VERSION ""

NS_ :

BS_:

BU_: XXX

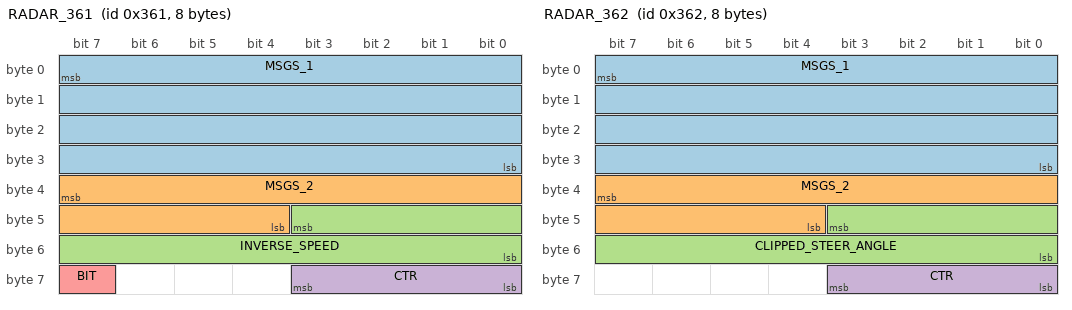
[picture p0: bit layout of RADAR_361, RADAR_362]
BO_ 865 RADAR_361: 8 XXX
 SG_ MSGS_1 : 7|32@0+ (1,0) [0|4294967295] "" XXX
 SG_ MSGS_2 : 39|12@0+ (1,0) [0|4095] "" XXX
 SG_ INVERSE_SPEED : 43|12@0- (1,0) [-2048|2047] "" XXX
 SG_ CTR : 59|4@0+ (1,0) [0|15] "" XXX
 SG_ BIT : 63|1@0+ (1,0) [0|1] "" XXX

BO_ 866 RADAR_362: 8 XXX
 SG_ MSGS_1 : 7|32@0+ (1,0) [0|4294967295] "" XXX
 SG_ MSGS_2 : 39|12@0+ (1,0) [0|4095] "" XXX
 SG_ CLIPPED_STEER_ANGLE : 43|12@0+ (1,0) [0|4095] "" XXX
 SG_ CTR : 59|4@0+ (1,0) [0|15] "" XXX

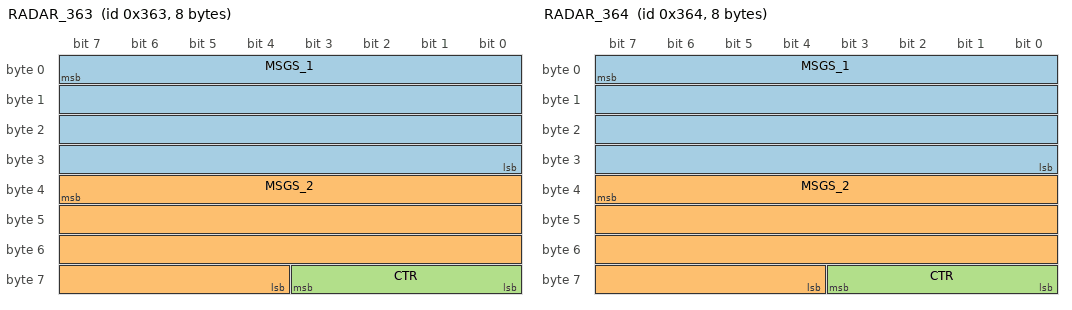
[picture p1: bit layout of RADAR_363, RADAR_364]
BO_ 867 RADAR_363: 8 XXX
 SG_ MSGS_1 : 7|32@0+ (1,0) [0|4294967295] "" XXX
 SG_ MSGS_2 : 39|28@0+ (1,0) [0|268435455] "" XXX
 SG_ CTR : 59|4@0+ (1,0) [0|15] "" XXX

BO_ 868 RADAR_364: 8 XXX
 SG_ MSGS_1 : 7|32@0+ (1,0) [0|4294967295] "" XXX
 SG_ MSGS_2 : 39|28@0+ (1,0) [0|268435455] "" XXX
 SG_ CTR : 59|4@0+ (1,0) [0|15] "" XXX

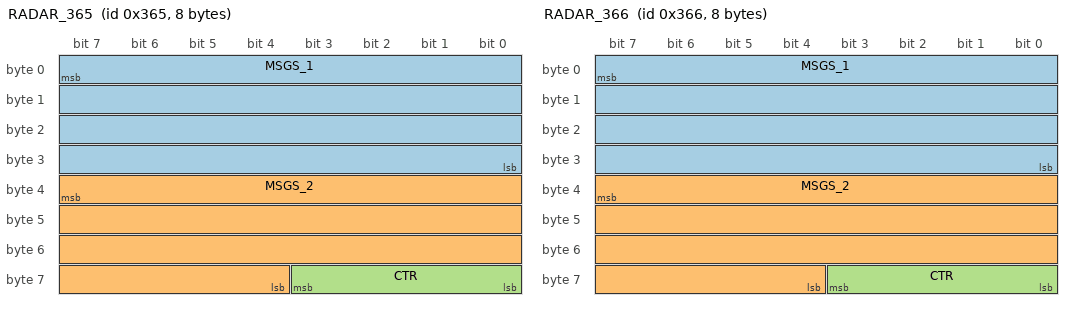
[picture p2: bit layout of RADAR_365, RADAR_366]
BO_ 869 RADAR_365: 8 XXX
 SG_ MSGS_1 : 7|32@0+ (1,0) [0|4294967295] "" XXX
 SG_ MSGS_2 : 39|28@0+ (1,0) [0|268435455] "" XXX
 SG_ CTR : 59|4@0+ (1,0) [0|15] "" XXX

BO_ 870 RADAR_366: 8 XXX
 SG_ MSGS_1 : 7|32@0+ (1,0) [0|4294967295] "" XXX
 SG_ MSGS_2 : 39|28@0+ (1,0) [0|268435455] "" XXX
 SG_ CTR : 59|4@0+ (1,0) [0|15] "" XXX
